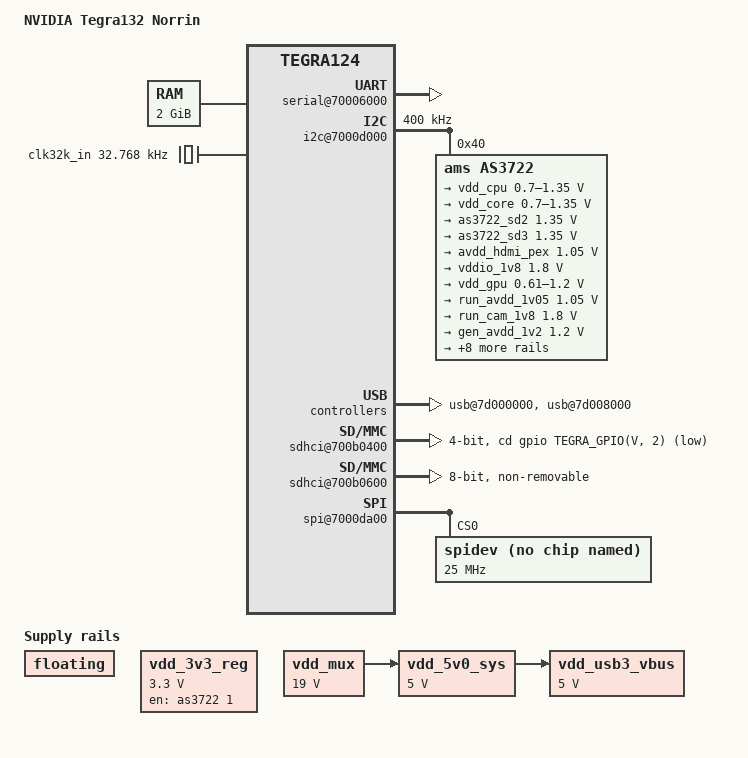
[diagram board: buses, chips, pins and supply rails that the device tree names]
/dts-v1/;

#include <dt-bindings/input/input.h>
#include "tegra132.dtsi"

/ {
	model = "NVIDIA Tegra132 Norrin";
	compatible = "nvidia,norrin", "nvidia,tegra132", "nvidia,tegra124";

	aliases {
		rtc0 = "/i2c@7000d000/as3722@40";
		rtc1 = "/rtc@7000e000";
	};

	memory {
		reg = <0x0 0x80000000 0x0 0x80000000>;
	};

	pinmux@70000868 {
		pinctrl-names = "default";
		pinctrl-0 = <&state_default>;

		state_default: pinmux@0 {
			dap_mclk1_pw4 {
				nvidia,pins = "dap_mclk1_pw4";
				nvidia,function = "extperiph1";
				nvidia,pull = <TEGRA_PIN_PULL_NONE>;
				nvidia,tristate = <TEGRA_PIN_DISABLE>;
				nvidia,enable-input = <TEGRA_PIN_DISABLE>;
			};
			dap2_din_pa4 {
				nvidia,pins = "dap2_din_pa4";
				nvidia,function = "i2s1";
				nvidia,pull = <TEGRA_PIN_PULL_NONE>;
				nvidia,tristate = <TEGRA_PIN_DISABLE>;
				nvidia,enable-input = <TEGRA_PIN_ENABLE>;
			};
			dap2_dout_pa5 {
				nvidia,pins = "dap2_dout_pa5",
						"dap2_fs_pa2",
						"dap2_sclk_pa3";
				nvidia,function = "i2s1";
				nvidia,pull = <TEGRA_PIN_PULL_NONE>;
				nvidia,tristate = <TEGRA_PIN_DISABLE>;
				nvidia,enable-input = <TEGRA_PIN_DISABLE>;
			};
			dap3_dout_pp2 {
				nvidia,pins = "dap3_dout_pp2";
				nvidia,function = "i2s2";
				nvidia,pull = <TEGRA_PIN_PULL_DOWN>;
				nvidia,tristate = <TEGRA_PIN_DISABLE>;
				nvidia,enable-input = <TEGRA_PIN_DISABLE>;
			};
			dvfs_pwm_px0 {
				nvidia,pins = "dvfs_pwm_px0",
						"dvfs_clk_px2";
				nvidia,function = "cldvfs";
				nvidia,pull = <TEGRA_PIN_PULL_NONE>;
				nvidia,tristate = <TEGRA_PIN_DISABLE>;
				nvidia,enable-input = <TEGRA_PIN_DISABLE>;
			};
			ulpi_clk_py0 {
				nvidia,pins = "ulpi_clk_py0",
						"ulpi_nxt_py2",
						"ulpi_stp_py3";
				nvidia,function = "spi1";
				nvidia,pull = <TEGRA_PIN_PULL_NONE>;
				nvidia,tristate = <TEGRA_PIN_DISABLE>;
				nvidia,enable-input = <TEGRA_PIN_DISABLE>;
			};
			ulpi_dir_py1 {
				nvidia,pins = "ulpi_dir_py1";
				nvidia,function = "spi1";
				nvidia,pull = <TEGRA_PIN_PULL_NONE>;
				nvidia,tristate = <TEGRA_PIN_DISABLE>;
				nvidia,enable-input = <TEGRA_PIN_ENABLE>;
			};
			cam_i2c_scl_pbb1 {
				nvidia,pins = "cam_i2c_scl_pbb1",
						"cam_i2c_sda_pbb2";
				nvidia,function = "i2c3";
				nvidia,pull = <TEGRA_PIN_PULL_NONE>;
				nvidia,tristate = <TEGRA_PIN_DISABLE>;
				nvidia,enable-input = <TEGRA_PIN_ENABLE>;
				nvidia,lock = <TEGRA_PIN_DISABLE>;
				nvidia,open-drain = <TEGRA_PIN_ENABLE>;
			};
			gen2_i2c_scl_pt5 {
				nvidia,pins = "gen2_i2c_scl_pt5",
						"gen2_i2c_sda_pt6";
				nvidia,function = "i2c2";
				nvidia,pull = <TEGRA_PIN_PULL_NONE>;
				nvidia,tristate = <TEGRA_PIN_DISABLE>;
				nvidia,enable-input = <TEGRA_PIN_ENABLE>;
				nvidia,lock = <TEGRA_PIN_DISABLE>;
				nvidia,open-drain = <TEGRA_PIN_ENABLE>;
			};
			pj7 {
				nvidia,pins = "pj7";
				nvidia,function = "uartd";
				nvidia,pull = <TEGRA_PIN_PULL_NONE>;
				nvidia,tristate = <TEGRA_PIN_DISABLE>;
				nvidia,enable-input = <TEGRA_PIN_DISABLE>;
			};
			spdif_in_pk6 {
				nvidia,pins = "spdif_in_pk6";
				nvidia,function = "spdif";
				nvidia,pull = <TEGRA_PIN_PULL_DOWN>;
				nvidia,tristate = <TEGRA_PIN_DISABLE>;
				nvidia,enable-input = <TEGRA_PIN_DISABLE>;
			};
			pk7 {
				nvidia,pins = "pk7";
				nvidia,function = "uartd";
				nvidia,pull = <TEGRA_PIN_PULL_NONE>;
				nvidia,tristate = <TEGRA_PIN_DISABLE>;
				nvidia,enable-input = <TEGRA_PIN_DISABLE>;
			};
			pg4 {
				nvidia,pins = "pg4",
						"pg5",
						"pg6",
						"pi3";
				nvidia,function = "spi4";
				nvidia,pull = <TEGRA_PIN_PULL_NONE>;
				nvidia,tristate = <TEGRA_PIN_DISABLE>;
				nvidia,enable-input = <TEGRA_PIN_DISABLE>;
			};
			pg7 {
				nvidia,pins = "pg7";
				nvidia,function = "spi4";
				nvidia,pull = <TEGRA_PIN_PULL_NONE>;
				nvidia,tristate = <TEGRA_PIN_DISABLE>;
				nvidia,enable-input = <TEGRA_PIN_ENABLE>;
			};
			ph1 {
				nvidia,pins = "ph1";
				nvidia,function = "pwm1";
				nvidia,pull = <TEGRA_PIN_PULL_NONE>;
				nvidia,tristate = <TEGRA_PIN_DISABLE>;
				nvidia,enable-input = <TEGRA_PIN_DISABLE>;
			};
			pk0 {
				nvidia,pins = "pk0",
						"kb_row15_ps7",
						"clk_32k_out_pa0";
				nvidia,function = "soc";
				nvidia,pull = <TEGRA_PIN_PULL_UP>;
				nvidia,tristate = <TEGRA_PIN_DISABLE>;
				nvidia,enable-input = <TEGRA_PIN_ENABLE>;
			};
			sdmmc1_clk_pz0 {
				nvidia,pins = "sdmmc1_clk_pz0";
				nvidia,function = "sdmmc1";
				nvidia,pull = <TEGRA_PIN_PULL_NONE>;
				nvidia,tristate = <TEGRA_PIN_DISABLE>;
				nvidia,enable-input = <TEGRA_PIN_ENABLE>;
			};
			sdmmc1_cmd_pz1 {
				nvidia,pins = "sdmmc1_cmd_pz1",
						"sdmmc1_dat0_py7",
						"sdmmc1_dat1_py6",
						"sdmmc1_dat2_py5",
						"sdmmc1_dat3_py4";
				nvidia,function = "sdmmc1";
				nvidia,pull = <TEGRA_PIN_PULL_UP>;
				nvidia,tristate = <TEGRA_PIN_DISABLE>;
				nvidia,enable-input = <TEGRA_PIN_ENABLE>;
			};
			sdmmc3_clk_pa6 {
				nvidia,pins = "sdmmc3_clk_pa6";
				nvidia,function = "sdmmc3";
				nvidia,pull = <TEGRA_PIN_PULL_NONE>;
				nvidia,tristate = <TEGRA_PIN_DISABLE>;
				nvidia,enable-input = <TEGRA_PIN_ENABLE>;
			};
			sdmmc3_cmd_pa7 {
				nvidia,pins = "sdmmc3_cmd_pa7",
						"sdmmc3_dat0_pb7",
						"sdmmc3_dat1_pb6",
						"sdmmc3_dat2_pb5",
						"sdmmc3_dat3_pb4",
						"kb_col4_pq4",
						"sdmmc3_clk_lb_out_pee4",
						"sdmmc3_clk_lb_in_pee5",
						"sdmmc3_cd_n_pv2";
				nvidia,function = "sdmmc3";
				nvidia,pull = <TEGRA_PIN_PULL_UP>;
				nvidia,tristate = <TEGRA_PIN_DISABLE>;
				nvidia,enable-input = <TEGRA_PIN_ENABLE>;
			};
			sdmmc4_clk_pcc4 {
				nvidia,pins = "sdmmc4_clk_pcc4";
				nvidia,function = "sdmmc4";
				nvidia,pull = <TEGRA_PIN_PULL_NONE>;
				nvidia,tristate = <TEGRA_PIN_DISABLE>;
				nvidia,enable-input = <TEGRA_PIN_ENABLE>;
			};
			sdmmc4_cmd_pt7 {
				nvidia,pins = "sdmmc4_cmd_pt7",
						"sdmmc4_dat0_paa0",
						"sdmmc4_dat1_paa1",
						"sdmmc4_dat2_paa2",
						"sdmmc4_dat3_paa3",
						"sdmmc4_dat4_paa4",
						"sdmmc4_dat5_paa5",
						"sdmmc4_dat6_paa6",
						"sdmmc4_dat7_paa7";
				nvidia,function = "sdmmc4";
				nvidia,pull = <TEGRA_PIN_PULL_UP>;
				nvidia,tristate = <TEGRA_PIN_DISABLE>;
				nvidia,enable-input = <TEGRA_PIN_ENABLE>;
			};
			mic_det_l {
				nvidia,pins = "kb_row7_pr7";
				nvidia,function = "rsvd2";
				nvidia,pull = <TEGRA_PIN_PULL_UP>;
				nvidia,tristate = <TEGRA_PIN_DISABLE>;
				nvidia,enable-input = <TEGRA_PIN_ENABLE>;
			};
			kb_row10_ps2 {
				nvidia,pins = "kb_row10_ps2";
				nvidia,function = "uarta";
				nvidia,pull = <TEGRA_PIN_PULL_UP>;
				nvidia,tristate = <TEGRA_PIN_DISABLE>;
				nvidia,enable-input = <TEGRA_PIN_ENABLE>;
			};
			kb_row9_ps1 {
				nvidia,pins = "kb_row9_ps1";
				nvidia,function = "uarta";
				nvidia,pull = <TEGRA_PIN_PULL_NONE>;
				nvidia,tristate = <TEGRA_PIN_DISABLE>;
				nvidia,enable-input = <TEGRA_PIN_DISABLE>;
			};
			pwr_i2c_scl_pz6 {
				nvidia,pins = "pwr_i2c_scl_pz6",
						"pwr_i2c_sda_pz7";
				nvidia,function = "i2cpwr";
				nvidia,pull = <TEGRA_PIN_PULL_NONE>;
				nvidia,tristate = <TEGRA_PIN_DISABLE>;
				nvidia,enable-input = <TEGRA_PIN_ENABLE>;
				nvidia,lock = <TEGRA_PIN_DISABLE>;
				nvidia,open-drain = <TEGRA_PIN_ENABLE>;
			};
			jtag_rtck {
				nvidia,pins = "jtag_rtck";
				nvidia,function = "rtck";
				nvidia,pull = <TEGRA_PIN_PULL_UP>;
				nvidia,tristate = <TEGRA_PIN_DISABLE>;
				nvidia,enable-input = <TEGRA_PIN_DISABLE>;

			};
			clk_32k_in {
				nvidia,pins = "clk_32k_in";
				nvidia,function = "clk";
				nvidia,pull = <TEGRA_PIN_PULL_NONE>;
				nvidia,tristate = <TEGRA_PIN_DISABLE>;
				nvidia,enable-input = <TEGRA_PIN_ENABLE>;
			};
			core_pwr_req {
				nvidia,pins = "core_pwr_req";
				nvidia,function = "pwron";
				nvidia,pull = <TEGRA_PIN_PULL_NONE>;
				nvidia,tristate = <TEGRA_PIN_DISABLE>;
				nvidia,enable-input = <TEGRA_PIN_DISABLE>;
			};
			cpu_pwr_req {
				nvidia,pins = "cpu_pwr_req";
				nvidia,function = "cpu";
				nvidia,pull = <TEGRA_PIN_PULL_NONE>;
				nvidia,tristate = <TEGRA_PIN_DISABLE>;
				nvidia,enable-input = <TEGRA_PIN_DISABLE>;
			};
			kb_col0_ap {
				nvidia,pins = "kb_col0_pq0";
				nvidia,function = "rsvd4";
				nvidia,pull = <TEGRA_PIN_PULL_UP>;
				nvidia,tristate = <TEGRA_PIN_DISABLE>;
				nvidia,enable-input = <TEGRA_PIN_ENABLE>;
			};
			en_vdd_sd {
				nvidia,pins = "kb_row0_pr0";
				nvidia,function = "rsvd4";
				nvidia,pull = <TEGRA_PIN_PULL_NONE>;
				nvidia,tristate = <TEGRA_PIN_DISABLE>;
				nvidia,enable-input = <TEGRA_PIN_DISABLE>;
			};
			lid_open {
				nvidia,pins = "kb_row4_pr4";
				nvidia,function = "rsvd3";
				nvidia,pull = <TEGRA_PIN_PULL_UP>;
				nvidia,tristate = <TEGRA_PIN_DISABLE>;
				nvidia,enable-input = <TEGRA_PIN_ENABLE>;
			};
			pwr_int_n {
				nvidia,pins = "pwr_int_n";
				nvidia,function = "pmi";
				nvidia,pull = <TEGRA_PIN_PULL_UP>;
				nvidia,tristate = <TEGRA_PIN_DISABLE>;
				nvidia,enable-input = <TEGRA_PIN_ENABLE>;
			};
			reset_out_n {
				nvidia,pins = "reset_out_n";
				nvidia,function = "reset_out_n";
				nvidia,pull = <TEGRA_PIN_PULL_NONE>;
				nvidia,tristate = <TEGRA_PIN_DISABLE>;
				nvidia,enable-input = <TEGRA_PIN_DISABLE>;
			};
			clk3_out_pee0 {
				nvidia,pins = "clk3_out_pee0";
				nvidia,function = "extperiph3";
				nvidia,pull = <TEGRA_PIN_PULL_NONE>;
				nvidia,tristate = <TEGRA_PIN_DISABLE>;
				nvidia,enable-input = <TEGRA_PIN_DISABLE>;
			};
			gen1_i2c_scl_pc4 {
				nvidia,pins = "gen1_i2c_scl_pc4",
						"gen1_i2c_sda_pc5";
				nvidia,function = "i2c1";
				nvidia,pull = <TEGRA_PIN_PULL_NONE>;
				nvidia,tristate = <TEGRA_PIN_DISABLE>;
				nvidia,enable-input = <TEGRA_PIN_ENABLE>;
				nvidia,lock = <TEGRA_PIN_DISABLE>;
				nvidia,open-drain = <TEGRA_PIN_ENABLE>;
			};
			hdmi_cec_pee3 {
				nvidia,pins = "hdmi_cec_pee3";
				nvidia,function = "cec";
				nvidia,pull = <TEGRA_PIN_PULL_NONE>;
				nvidia,tristate = <TEGRA_PIN_DISABLE>;
				nvidia,enable-input = <TEGRA_PIN_ENABLE>;
				nvidia,lock = <TEGRA_PIN_DISABLE>;
				nvidia,open-drain = <TEGRA_PIN_DISABLE>;
			};
			hdmi_int_pn7 {
				nvidia,pins = "hdmi_int_pn7";
				nvidia,function = "rsvd1";
				nvidia,pull = <TEGRA_PIN_PULL_DOWN>;
				nvidia,tristate = <TEGRA_PIN_DISABLE>;
				nvidia,enable-input = <TEGRA_PIN_ENABLE>;
			};
			ddc_scl_pv4 {
				nvidia,pins = "ddc_scl_pv4",
						"ddc_sda_pv5";
				nvidia,function = "i2c4";
				nvidia,pull = <TEGRA_PIN_PULL_DOWN>;
				nvidia,tristate = <TEGRA_PIN_DISABLE>;
				nvidia,enable-input = <TEGRA_PIN_ENABLE>;
				nvidia,lock = <TEGRA_PIN_DISABLE>;
				nvidia,rcv-sel = <TEGRA_PIN_PULL_DOWN>;
			};
			usb_vbus_en0_pn4 {
				nvidia,pins = "usb_vbus_en0_pn4",
						"usb_vbus_en1_pn5",
						"usb_vbus_en2_pff1";
				nvidia,function = "usb";
				nvidia,pull = <TEGRA_PIN_PULL_UP>;
				nvidia,tristate = <TEGRA_PIN_ENABLE>;
				nvidia,enable-input = <TEGRA_PIN_ENABLE>;
				nvidia,lock = <TEGRA_PIN_DISABLE>;
				nvidia,open-drain = <TEGRA_PIN_DISABLE>;
			};
			drive_sdio1 {
				nvidia,pins = "drive_sdio1";
				nvidia,high-speed-mode = <TEGRA_PIN_ENABLE>;
				nvidia,schmitt = <TEGRA_PIN_DISABLE>;
				nvidia,low-power-mode = <TEGRA_PIN_LP_DRIVE_DIV_1>;
				nvidia,pull-down-strength = <36>;
				nvidia,pull-up-strength = <20>;
				nvidia,slew-rate-rising = <TEGRA_PIN_SLEW_RATE_SLOW>;
				nvidia,slew-rate-falling = <TEGRA_PIN_SLEW_RATE_SLOW>;
			};
			drive_sdio3 {
				nvidia,pins = "drive_sdio3";
				nvidia,high-speed-mode = <TEGRA_PIN_ENABLE>;
				nvidia,schmitt = <TEGRA_PIN_DISABLE>;
				nvidia,low-power-mode = <TEGRA_PIN_LP_DRIVE_DIV_1>;
				nvidia,pull-down-strength = <22>;
				nvidia,pull-up-strength = <36>;
				nvidia,slew-rate-rising = <TEGRA_PIN_SLEW_RATE_FASTEST>;
				nvidia,slew-rate-falling = <TEGRA_PIN_SLEW_RATE_FASTEST>;
			};
			drive_gma {
				nvidia,pins = "drive_gma";
				nvidia,high-speed-mode = <TEGRA_PIN_ENABLE>;
				nvidia,schmitt = <TEGRA_PIN_DISABLE>;
				nvidia,low-power-mode = <TEGRA_PIN_LP_DRIVE_DIV_1>;
				nvidia,pull-down-strength = <2>;
				nvidia,pull-up-strength = <1>;
				nvidia,slew-rate-rising = <TEGRA_PIN_SLEW_RATE_FASTEST>;
				nvidia,slew-rate-falling = <TEGRA_PIN_SLEW_RATE_FASTEST>;
				nvidia,drive-type = <1>;
			};
			ac_ok {
				nvidia,pins = "pj0";
				nvidia,function = "gmi";
				nvidia,pull = <TEGRA_PIN_PULL_UP>;
				nvidia,tristate = <TEGRA_PIN_ENABLE>;
				nvidia,enable-input = <TEGRA_PIN_ENABLE>;
			};
			codec_irq_l {
				nvidia,pins = "ph4";
				nvidia,function = "gmi";
				nvidia,pull = <TEGRA_PIN_PULL_NONE>;
				nvidia,tristate = <TEGRA_PIN_DISABLE>;
				nvidia,enable-input = <TEGRA_PIN_ENABLE>;
			};
			lcd_bl_en {
				nvidia,pins = "ph2";
				nvidia,function = "gmi";
				nvidia,pull = <TEGRA_PIN_PULL_DOWN>;
				nvidia,tristate = <TEGRA_PIN_DISABLE>;
				nvidia,enable-input = <TEGRA_PIN_DISABLE>;
			};
			touch_irq_l {
				nvidia,pins = "gpio_w3_aud_pw3";
				nvidia,function = "spi6";
				nvidia,pull = <TEGRA_PIN_PULL_NONE>;
				nvidia,tristate = <TEGRA_PIN_ENABLE>;
				nvidia,enable-input = <TEGRA_PIN_ENABLE>;
			};
			tpm_davint_l {
				nvidia,pins = "ph6";
				nvidia,function = "gmi";
				nvidia,pull = <TEGRA_PIN_PULL_NONE>;
				nvidia,tristate = <TEGRA_PIN_ENABLE>;
				nvidia,enable-input = <TEGRA_PIN_ENABLE>;
			};
			ts_irq_l {
				nvidia,pins = "pk2";
				nvidia,function = "gmi";
				nvidia,pull = <TEGRA_PIN_PULL_NONE>;
				nvidia,tristate = <TEGRA_PIN_ENABLE>;
				nvidia,enable-input = <TEGRA_PIN_ENABLE>;
			};
			ts_reset_l {
				nvidia,pins = "pk4";
				nvidia,function = "gmi";
				nvidia,pull = <1>;
				nvidia,tristate = <TEGRA_PIN_DISABLE>;
				nvidia,enable-input = <TEGRA_PIN_DISABLE>;
			};
			ts_shdn_l {
				nvidia,pins = "pk1";
				nvidia,function = "gmi";
				nvidia,pull = <TEGRA_PIN_PULL_UP>;
				nvidia,tristate = <TEGRA_PIN_DISABLE>;
				nvidia,enable-input = <TEGRA_PIN_DISABLE>;
			};
			ph7 {
				nvidia,pins = "ph7";
				nvidia,function = "gmi";
				nvidia,pull = <TEGRA_PIN_PULL_NONE>;
				nvidia,tristate = <TEGRA_PIN_DISABLE>;
				nvidia,enable-input = <TEGRA_PIN_ENABLE>;
			};
			sensor_irq_l {
				nvidia,pins = "pi6";
				nvidia,function = "gmi";
				nvidia,pull = <TEGRA_PIN_PULL_NONE>;
				nvidia,tristate = <TEGRA_PIN_DISABLE>;
				nvidia,enable-input = <TEGRA_PIN_ENABLE>;
			};
			wifi_en {
				nvidia,pins = "gpio_x7_aud_px7";
				nvidia,function = "rsvd4";
				nvidia,pull = <TEGRA_PIN_PULL_NONE>;
				nvidia,tristate = <TEGRA_PIN_DISABLE>;
				nvidia,enable-input = <TEGRA_PIN_DISABLE>;
			};
			chromeos_write_protect {
				nvidia,pins = "kb_row1_pr1";
				nvidia,function = "rsvd4";
				nvidia,pull = <TEGRA_PIN_PULL_NONE>;
				nvidia,tristate = <TEGRA_PIN_DISABLE>;
				nvidia,enable-input = <TEGRA_PIN_ENABLE>;
			};
			hp_det_l {
				nvidia,pins = "pi7";
				nvidia,function = "rsvd1";
				nvidia,pull = <TEGRA_PIN_PULL_NONE>;
				nvidia,tristate = <TEGRA_PIN_DISABLE>;
				nvidia,enable-input = <TEGRA_PIN_ENABLE>;
			};
			soc_warm_reset_l {
				nvidia,pins = "pi5";
				nvidia,function = "gmi";
				nvidia,pull = <TEGRA_PIN_PULL_UP>;
				nvidia,tristate = <TEGRA_PIN_DISABLE>;
				nvidia,enable-input = <TEGRA_PIN_DISABLE>;
			};
		};
	};

	serial@70006000 {
		status = "okay";
	};

	rtc {
		nvidia,pmc-wakeup = <&pmc 1 16 4>;
	};

	i2c@7000d000 {
		status = "okay";
		clock-frequency = <400000>;

		as3722: pmic@40 {
			compatible = "ams,as3722";
			reg = <0x40>;

			interrupts = <GIC_SPI 86 IRQ_TYPE_NONE>;
			interrupt-controller;
			#interrupt-cells = <2>;
			nvidia,pmc-wakeup = <&pmc 1 18 8>;

			gpio-controller;
			#gpio-cells = <2>;

			ams,system-power-controller;

			pinctrl-names = "default";
			pinctrl-0 = <&as3722_default>;

			pinctrl@0 {
				gpio6 {
					pins = "gpio6";
					function = "clk32k-out";
					bias-pull-down;
				};
			};
			as3722_default: pinmux@0 {
				gpio0 {
					pins = "gpio0";
					function = "gpio";
					bias-pull-down;
				};

				gpio1 {
					pins = "gpio1";
					function = "gpio";
					bias-pull-up;
				};

				gpio2_4_7 {
					pins = "gpio2", "gpio4", "gpio7";
					function = "gpio";
					bias-pull-up;
				};

				gpio3 {
					pins = "gpio3";
					function = "gpio";
					bias-high-impedance;
				};

				gpio5 {
					pins = "gpio5";
					function = "clk32k-out";
					bias-pull-down;
				};
			};

			regulators {
				vsup-sd2-supply = <&floating>;
				vsup-sd3-supply = <&floating>;
				vsup-sd4-supply = <&floating>;
				vsup-sd5-supply = <&floating>;
				vin-ldo0-supply = <&as3722_sd2>;
				vin-ldo1-6-supply = <&floating>;
				vin-ldo2-5-7-supply = <&vddio_1v8>;
				vin-ldo3-4-supply = <&floating>;
				vin-ldo9-10-supply = <&floating>;
				vin-ldo11-supply = <&floating>;

				vdd_cpu: sd0 {
					regulator-name = "vdd_cpu";
					regulator-min-microvolt = <700000>;
					regulator-max-microvolt = <1350000>;
					regulator-always-on;
					regulator-suspend-mem-disabled;
					ams,ext-control = <2>;
				};

				sd1 {
					regulator-name = "vdd_core";
					regulator-min-microvolt = <700000>;
					regulator-max-microvolt = <1350000>;
					regulator-max-microamp = <3500000>;
					regulator-always-on;
					regulator-suspend-mem-disabled;
					ams,ext-control = <1>;
					ams,standby-sequence = <6>;
				};

				as3722_sd2: sd2 {
					regulator-name = "vddio_ddr";
					regulator-min-microvolt = <1350000>;
					regulator-max-microvolt = <1350000>;
					regulator-always-on;
					regulator-suspend-mem-enabled;
				};

				as3722_sd3: sd3 {
					regulator-name = "sd3";
					regulator-min-microvolt = <1350000>;
					regulator-max-microvolt = <1350000>;
					regulator-always-on;
					regulator-suspend-mem-enabled;
				};

				avdd_hdmi_pex: sd4 {
					regulator-name = "avdd-hdmi-pex";
					regulator-min-microvolt = <1050000>;
					regulator-max-microvolt = <1050000>;
					regulator-boot-on;
					regulator-always-on;
					regulator-suspend-mem-disabled;
					ams,standby-sequence = <3>;
				};

				vddio_1v8: sd5 {
					regulator-name = "vdd-1v8";
					regulator-min-microvolt = <1800000>;
					regulator-max-microvolt = <1800000>;
					regulator-always-on;
					regulator-suspend-mem-enabled;
				};

				vdd_gpu: sd6 {
					regulator-name = "vdd_gpu";
					regulator-min-microvolt = <610000>;
					regulator-max-microvolt = <1200000>;
					regulator-boot-on;
					regulator-always-on;
					regulator-suspend-mem-enabled;
					regulator-suspend-mem-microvolt = <610000>;
					ams,standby-sequence = <0>;
				};

				run_avdd_1v05: ldo0 {
					regulator-name = "avdd-pll";
					regulator-min-microvolt = <1050000>;
					regulator-max-microvolt = <1050000>;
					regulator-always-on;
					regulator-suspend-mem-disabled;
					ams,ext-control = <1>;
					ams,standby-sequence = <5>;
				};

				run_cam_1v8: ldo1 {
					regulator-name = "vdd_cam";
					regulator-min-microvolt = <1800000>;
					regulator-max-microvolt = <1800000>;
					regulator-suspend-mem-disabled;
				};

				gen_avdd_1v2: ldo2 {
					regulator-name = "vddio_hsic";
					regulator-min-microvolt = <1200000>;
					regulator-max-microvolt = <1200000>;
					regulator-always-on;
					regulator-suspend-mem-disabled;
					ams,standby-sequence = <2>;
				};

				lp0_vdd_rtc_1v0: ldo3 {
					regulator-name = "vdd_rtc";
					regulator-min-microvolt = <1000000>;
					regulator-max-microvolt = <1000000>;
					regulator-always-on;
					regulator-suspend-mem-enabled;
					ams,enable-tracking;
				};

				run_cam_2v8: ldo4 {
					regulator-name = "avdd_cam";
					regulator-min-microvolt = <2800000>;
					regulator-max-microvolt = <2800000>;
					regulator-suspend-mem-disabled;
					ams,standby-sequence = <1>;
				};

				run_cam_front_1v2: ldo5 {
					regulator-name = "vdig";
					regulator-min-microvolt = <1200000>;
					regulator-max-microvolt = <1200000>;
					regulator-suspend-mem-disabled;
				};

				vddio_sdmmc3: ldo6 {
					regulator-name = "vddio_sdmmc";
					regulator-min-microvolt = <3300000>;
					regulator-max-microvolt = <3300000>;
					regulator-suspend-mem-disabled;
				};

				run_cam_rear_en_1v05: ldo7 {
					regulator-name = "vdd_cam1";
					regulator-min-microvolt = <1050000>;
					regulator-max-microvolt = <1050000>;
					regulator-suspend-mem-disabled;
				};

				run_touch_2v8: ldo9 {
					regulator-name = "avdd";
					regulator-min-microvolt = <2800000>;
					regulator-max-microvolt = <2800000>;
					regulator-suspend-mem-disabled;
				};

				run_cam_af_2v8: ldo10 {
					regulator-name = "avdd_af1_cam";
					regulator-min-microvolt = <2800000>;
					regulator-max-microvolt = <2800000>;
					regulator-suspend-mem-disabled;
				};

				run_vpp_fuse_1v8: ldo11 {
					regulator-name = "vpp_fuse";
					regulator-min-microvolt = <1800000>;
					regulator-max-microvolt = <1800000>;
					regulator-suspend-mem-disabled;
				};
			};
		};
	};

	memory-controller@7001b000 {
		emc-table@0 {
			#address-cells = <1>;
			#size-cells = <0>;
			nvidia,ram-code = <0>;
			emc-table@12751 {
				compatible = "nvidia,tegra12-emc-table";
				reg = <12750>;
				clock-frequency = <12750>;
				nvidia,revision = <0x19>;
				nvidia,emc-min-mv = <800>;
				nvidia,gk20a-min-mv = <800>;
				nvidia,src-sel-reg = <0x4000003e>;
				nvidia,burst-regs-num = <165>;
				nvidia,burst-up-down-regs-num = <31>;
				nvidia,emc-registers = <0x00000000 0x00000003
					0x00000000 0x00000000 0x00000000 0x00000004
					0x0000000a 0x00000003 0x0000000b 0x00000000
					0x00000000 0x00000003 0x00000003 0x00000000
					0x00000006 0x00000006 0x00000006 0x00000002
					0x00000000 0x00000005 0x00000005 0x00010000
					0x00000003 0x00000000 0x00000000 0x00000000
					0x00000000 0x00000004 0x0000000c 0x0000000d
					0x0000000f 0x00000060 0x00000000 0x00000018
					0x00000002 0x00000002 0x00000001 0x00000000
					0x00000007 0x0000000f 0x00000005 0x00000005
					0x00000004 0x00000005 0x00000004 0x00000000
					0x00000000 0x00000005 0x00000005 0x00000064
					0x00000000 0x00000000 0x00000000 0x106aa298
					0x002c00a0 0x00008000 0x00064000 0x00064000
					0x00064000 0x00064000 0x00064000 0x00064000
					0x00064000 0x00064000 0x00064000 0x00064000
					0x00064000 0x00064000 0x00064000 0x00064000
					0x00064000 0x00064000 0x00000000 0x00000000
					0x00000000 0x00000000 0x00000000 0x00000000
					0x00000000 0x00000000 0x00000000 0x00000000
					0x00014000 0x00000000 0x00000000 0x00014000
					0x00000000 0x00000000 0x00000000 0x00000000
					0x00000000 0x00000000 0x00000000 0x00000000
					0x00000000 0x00000000 0x00000000 0x00000000
					0x00000000 0x00000000 0x00000000 0x00000000
					0x00000000 0x00000000 0x00000000 0x00000000
					0x00000000 0x00000000 0x00000000 0x00000000
					0x000fc000 0x000fc000 0x000fc000 0x000fc000
					0x0000fc00 0x0000fc00 0x0000fc00 0x0000fc00
					0x10000280 0x00000000 0x00111111 0x0130b118
					0x00000000 0x00000000 0x77ffc081 0x00000707
					0x81f1f108 0x07070004 0x0000003f 0x016eeeee
					0x51451400 0x00514514 0x00514514 0x51451400
					0x0000003f 0x00000007 0x00000000 0x00000000
					0x00000042 0x000e000e 0x000e000e 0x00000000
					0x00000003 0x0000f2f3 0x800001c5 0x0000000a
					0x40040001 0x8000000a 0x00000001 0x00000001
					0x00000002 0x00000000 0x00000002 0x00000001
					0x00000002 0x00000008 0x00000003 0x00000002
					0x00000003 0x00000006 0x06030203 0x000a0402
					0x77e30303 0x70000f03 0x001f0000>;
				nvidia,emc-burst-up-down-regs = <0x00000001 0x00000007
					0x00ff00ff 0x00ff00ff 0x00ff00ff 0x00ff00ff
					0x00ff00ff 0x00ff00ff 0x00ff00ff 0x00ff0049
					0x00ff0080 0x00ff0004 0x00ff0004 0x000800ff
					0x000000ff 0x00ff0004 0x00ff00ff 0x00ff00ff
					0x00ff0024 0x00ff00ff 0x000000ff 0x000000ff
					0x00ff00ff 0x000000ff 0x00ff00ff 0x00ff00ff
					0x00ff00ff 0x00ff00ff 0x00ff00ff 0x00ff00ff
					0x00ff00ff>;
				nvidia,emc-zcal-cnt-long = <0x00000042>;
				nvidia,emc-acal-interval = <0x001fffff>;
				nvidia,emc-ctt-term-ctrl = <0x00000802>;
				nvidia,emc-cfg = <0x73240000>;
				nvidia,emc-cfg-2 = <0x000008c5>;
				nvidia,emc-sel-dpd-ctrl = <0x00040128>;
				nvidia,emc-cfg-dig-dll = <0x002c0068>;
				nvidia,emc-bgbias-ctl0 = <0x00000008>;
				nvidia,emc-auto-cal-config2 = <0x00000000>;
				nvidia,emc-auto-cal-config3 = <0x00000000>;
				nvidia,emc-auto-cal-config = <0xa1430000>;
				nvidia,emc-mode-reset = <0x80001221>;
				nvidia,emc-mode-1 = <0x80100003>;
				nvidia,emc-mode-2 = <0x80200008>;
				nvidia,emc-mode-4 = <0x00000000>;
				nvidia,emc-clock-latency-change = <57820>;
			};
			emc-table@20400 {
				compatible = "nvidia,tegra12-emc-table";
				reg = <20400>;
				clock-frequency = <20400>;
				nvidia,revision = <0x19>;
				nvidia,emc-min-mv = <800>;
				nvidia,gk20a-min-mv = <800>;
				nvidia,src-sel-reg = <0x40000026>;
				nvidia,burst-regs-num = <165>;
				nvidia,burst-up-down-regs-num = <31>;
				nvidia,emc-registers = <0x00000000 0x00000005
					0x00000000 0x00000000 0x00000000 0x00000004
					0x0000000a 0x00000003 0x0000000b 0x00000000
					0x00000000 0x00000003 0x00000003 0x00000000
					0x00000006 0x00000006 0x00000006 0x00000002
					0x00000000 0x00000005 0x00000005 0x00010000
					0x00000003 0x00000000 0x00000000 0x00000000
					0x00000000 0x00000004 0x0000000c 0x0000000d
					0x0000000f 0x0000009a 0x00000000 0x00000026
					0x00000002 0x00000002 0x00000001 0x00000000
					0x00000007 0x0000000f 0x00000006 0x00000006
					0x00000004 0x00000005 0x00000004 0x00000000
					0x00000000 0x00000005 0x00000005 0x000000a0
					0x00000000 0x00000000 0x00000000 0x106aa298
					0x002c00a0 0x00008000 0x00064000 0x00064000
					0x00064000 0x00064000 0x00064000 0x00064000
					0x00064000 0x00064000 0x00064000 0x00064000
					0x00064000 0x00064000 0x00064000 0x00064000
					0x00064000 0x00064000 0x00000000 0x00000000
					0x00000000 0x00000000 0x00000000 0x00000000
					0x00000000 0x00000000 0x00000000 0x00000000
					0x00014000 0x00000000 0x00000000 0x00014000
					0x00000000 0x00000000 0x00000000 0x00000000
					0x00000000 0x00000000 0x00000000 0x00000000
					0x00000000 0x00000000 0x00000000 0x00000000
					0x00000000 0x00000000 0x00000000 0x00000000
					0x00000000 0x00000000 0x00000000 0x00000000
					0x00000000 0x00000000 0x00000000 0x00000000
					0x000fc000 0x000fc000 0x000fc000 0x000fc000
					0x0000fc00 0x0000fc00 0x0000fc00 0x0000fc00
					0x10000280 0x00000000 0x00111111 0x0130b118
					0x00000000 0x00000000 0x77ffc081 0x00000707
					0x81f1f108 0x07070004 0x0000003f 0x016eeeee
					0x51451400 0x00514514 0x00514514 0x51451400
					0x0000003f 0x0000000b 0x00000000 0x00000000
					0x00000042 0x000e000e 0x000e000e 0x00000000
					0x00000003 0x0000f2f3 0x8000023a 0x0000000a
					0x40020001 0x80000012 0x00000001 0x00000001
					0x00000002 0x00000000 0x00000002 0x00000001
					0x00000002 0x00000008 0x00000003 0x00000002
					0x00000003 0x00000006 0x06030203 0x000a0402
					0x76230303 0x70000f03 0x001f0000>;
				nvidia,emc-burst-up-down-regs = <0x00000001 0x0000000a
					0x00ff00ff 0x00ff00ff 0x00ff00ff 0x00ff00ff
					0x00ff00ff 0x00ff00ff 0x00ff00ff 0x00ff0049
					0x00ff0080 0x00ff0004 0x00ff0004 0x000800ff
					0x000000ff 0x00ff0004 0x00ff00ff 0x00ff00ff
					0x00ff0024 0x00ff00ff 0x000000ff 0x000000ff
					0x00ff00ff 0x000000ff 0x00ff00ff 0x00ff00ff
					0x00ff00ff 0x00ff00ff 0x00ff00ff 0x00ff00ff
					0x00ff00ff>;
				nvidia,emc-zcal-cnt-long = <0x00000042>;
				nvidia,emc-acal-interval = <0x001fffff>;
				nvidia,emc-ctt-term-ctrl = <0x00000802>;
				nvidia,emc-cfg = <0x73240000>;
				nvidia,emc-cfg-2 = <0x000008c5>;
				nvidia,emc-sel-dpd-ctrl = <0x00040128>;
				nvidia,emc-cfg-dig-dll = <0x002c0068>;
				nvidia,emc-bgbias-ctl0 = <0x00000008>;
				nvidia,emc-auto-cal-config2 = <0x00000000>;
				nvidia,emc-auto-cal-config3 = <0x00000000>;
				nvidia,emc-auto-cal-config = <0xa1430000>;
				nvidia,emc-mode-reset = <0x80001221>;
				nvidia,emc-mode-1 = <0x80100003>;
				nvidia,emc-mode-2 = <0x80200008>;
				nvidia,emc-mode-4 = <0x00000000>;
				nvidia,emc-clock-latency-change = <35610>;
			};
			emc-table@40800 {
				compatible = "nvidia,tegra12-emc-table";
				reg = <40800>;
				clock-frequency = <40800>;
				nvidia,revision = <0x19>;
				nvidia,emc-min-mv = <800>;
				nvidia,gk20a-min-mv = <800>;
				nvidia,src-sel-reg = <0x40000012>;
				nvidia,burst-regs-num = <165>;
				nvidia,burst-up-down-regs-num = <31>;
				nvidia,emc-registers = <0x00000001 0x0000000a
					0x00000000 0x00000001 0x00000000 0x00000004
					0x0000000a 0x00000003 0x0000000b 0x00000000
					0x00000000 0x00000003 0x00000003 0x00000000
					0x00000006 0x00000006 0x00000006 0x00000002
					0x00000000 0x00000005 0x00000005 0x00010000
					0x00000003 0x00000000 0x00000000 0x00000000
					0x00000000 0x00000004 0x0000000c 0x0000000d
					0x0000000f 0x00000134 0x00000000 0x0000004d
					0x00000002 0x00000002 0x00000001 0x00000000
					0x00000008 0x0000000f 0x0000000c 0x0000000c
					0x00000004 0x00000005 0x00000004 0x00000000
					0x00000000 0x00000005 0x00000005 0x0000013f
					0x00000000 0x00000000 0x00000000 0x106aa298
					0x002c00a0 0x00008000 0x00064000 0x00064000
					0x00064000 0x00064000 0x00064000 0x00064000
					0x00064000 0x00064000 0x00064000 0x00064000
					0x00064000 0x00064000 0x00064000 0x00064000
					0x00064000 0x00064000 0x00000000 0x00000000
					0x00000000 0x00000000 0x00000000 0x00000000
					0x00000000 0x00000000 0x00000000 0x00000000
					0x00014000 0x00000000 0x00000000 0x00014000
					0x00000000 0x00000000 0x00000000 0x00000000
					0x00000000 0x00000000 0x00000000 0x00000000
					0x00000000 0x00000000 0x00000000 0x00000000
					0x00000000 0x00000000 0x00000000 0x00000000
					0x00000000 0x00000000 0x00000000 0x00000000
					0x00000000 0x00000000 0x00000000 0x00000000
					0x000fc000 0x000fc000 0x000fc000 0x000fc000
					0x0000fc00 0x0000fc00 0x0000fc00 0x0000fc00
					0x10000280 0x00000000 0x00111111 0x0130b118
					0x00000000 0x00000000 0x77ffc081 0x00000707
					0x81f1f108 0x07070004 0x0000003f 0x016eeeee
					0x51451400 0x00514514 0x00514514 0x51451400
					0x0000003f 0x00000015 0x00000000 0x00000000
					0x00000042 0x000e000e 0x000e000e 0x00000000
					0x00000003 0x0000f2f3 0x80000370 0x0000000a
					0xa0000001 0x80000017 0x00000001 0x00000001
					0x00000002 0x00000000 0x00000002 0x00000001
					0x00000002 0x00000008 0x00000003 0x00000002
					0x00000003 0x00000006 0x06030203 0x000a0402
					0x74a30303 0x70000f03 0x001f0000>;
				nvidia,emc-burst-up-down-regs = <0x00000001 0x00000014
					0x00ff00ff 0x00ff00ff 0x00ff00ff 0x00ff00ff
					0x00ff00ff 0x00ff00ff 0x00ff00ff 0x00ff0049
					0x00ff0080 0x00ff0004 0x00ff0004 0x000800ff
					0x000000ff 0x00ff0004 0x00ff00ff 0x00ff00ff
					0x00ff0024 0x00ff00ff 0x000000ff 0x000000ff
					0x00ff00ff 0x000000ff 0x00ff00ff 0x00ff00ff
					0x00ff00ff 0x00ff00ff 0x00ff00ff 0x00ff00ff
					0x00ff00ff>;
				nvidia,emc-zcal-cnt-long = <0x00000042>;
				nvidia,emc-acal-interval = <0x001fffff>;
				nvidia,emc-ctt-term-ctrl = <0x00000802>;
				nvidia,emc-cfg = <0x73240000>;
				nvidia,emc-cfg-2 = <0x000008c5>;
				nvidia,emc-sel-dpd-ctrl = <0x00040128>;
				nvidia,emc-cfg-dig-dll = <0x002c0068>;
				nvidia,emc-bgbias-ctl0 = <0x00000008>;
				nvidia,emc-auto-cal-config2 = <0x00000000>;
				nvidia,emc-auto-cal-config3 = <0x00000000>;
				nvidia,emc-auto-cal-config = <0xa1430000>;
				nvidia,emc-mode-reset = <0x80001221>;
				nvidia,emc-mode-1 = <0x80100003>;
				nvidia,emc-mode-2 = <0x80200008>;
				nvidia,emc-mode-4 = <0x00000000>;
				nvidia,emc-clock-latency-change = <20850>;
			};
			emc-table@68000 {
				compatible = "nvidia,tegra12-emc-table";
				reg = <68000>;
				clock-frequency = <68000>;
				nvidia,revision = <0x19>;
				nvidia,emc-min-mv = <800>;
				nvidia,gk20a-min-mv = <800>;
				nvidia,src-sel-reg = <0x4000000a>;
				nvidia,burst-regs-num = <165>;
				nvidia,burst-up-down-regs-num = <31>;
				nvidia,emc-registers = <0x00000003 0x00000011
					0x00000000 0x00000002 0x00000000 0x00000004
					0x0000000a 0x00000003 0x0000000b 0x00000000
					0x00000000 0x00000003 0x00000003 0x00000000
					0x00000006 0x00000006 0x00000006 0x00000002
					0x00000000 0x00000005 0x00000005 0x00010000
					0x00000003 0x00000000 0x00000000 0x00000000
					0x00000000 0x00000004 0x0000000c 0x0000000d
					0x0000000f 0x00000202 0x00000000 0x00000080
					0x00000002 0x00000002 0x00000001 0x00000000
					0x0000000f 0x0000000f 0x00000013 0x00000013
					0x00000004 0x00000005 0x00000004 0x00000001
					0x00000000 0x00000005 0x00000005 0x00000213
					0x00000000 0x00000000 0x00000000 0x106aa298
					0x002c00a0 0x00008000 0x00064000 0x00064000
					0x00064000 0x00064000 0x00064000 0x00064000
					0x00064000 0x00064000 0x00064000 0x00064000
					0x00064000 0x00064000 0x00064000 0x00064000
					0x00064000 0x00064000 0x00000000 0x00000000
					0x00000000 0x00000000 0x00000000 0x00000000
					0x00000000 0x00000000 0x00000000 0x00000000
					0x00014000 0x00000000 0x00000000 0x00014000
					0x00000000 0x00000000 0x00000000 0x00000000
					0x00000000 0x00000000 0x00000000 0x00000000
					0x00000000 0x00000000 0x00000000 0x00000000
					0x00000000 0x00000000 0x00000000 0x00000000
					0x00000000 0x00000000 0x00000000 0x00000000
					0x00000000 0x00000000 0x00000000 0x00000000
					0x000fc000 0x000fc000 0x000fc000 0x000fc000
					0x0000fc00 0x0000fc00 0x0000fc00 0x0000fc00
					0x10000280 0x00000000 0x00111111 0x0130b118
					0x00000000 0x00000000 0x77ffc081 0x00000707
					0x81f1f108 0x07070004 0x0000003f 0x016eeeee
					0x51451400 0x00514514 0x00514514 0x51451400
					0x0000003f 0x00000022 0x00000000 0x00000000
					0x00000042 0x000e000e 0x000e000e 0x00000000
					0x00000003 0x0000f2f3 0x8000050e 0x0000000a
					0x00000001 0x8000001e 0x00000001 0x00000001
					0x00000002 0x00000000 0x00000002 0x00000001
					0x00000002 0x00000008 0x00000003 0x00000002
					0x00000003 0x00000006 0x06030203 0x000a0402
					0x74230403 0x70000f03 0x001f0000>;
				nvidia,emc-burst-up-down-regs = <0x00000001 0x00000021
					0x00ff00ff 0x00ff00ff 0x00ff00b0 0x00ff00ff
					0x00ff00ec 0x00ff00ff 0x00ff00ec 0x00e90049
					0x00ff0080 0x00ff0004 0x00ff0004 0x000800ff
					0x000000ff 0x00ff0004 0x00ff00ff 0x00ff00a3
					0x00ff0024 0x00ff00ff 0x000000ff 0x000000ef
					0x00ff00ff 0x000000ef 0x00ff00ff 0x00ff00ff
					0x00ee00ef 0x00ff00ff 0x00ff00ff 0x00ff00ff
					0x00ff00ff>;
				nvidia,emc-zcal-cnt-long = <0x00000042>;
				nvidia,emc-acal-interval = <0x001fffff>;
				nvidia,emc-ctt-term-ctrl = <0x00000802>;
				nvidia,emc-cfg = <0x73240000>;
				nvidia,emc-cfg-2 = <0x000008c5>;
				nvidia,emc-sel-dpd-ctrl = <0x00040128>;
				nvidia,emc-cfg-dig-dll = <0x002c0068>;
				nvidia,emc-bgbias-ctl0 = <0x00000008>;
				nvidia,emc-auto-cal-config2 = <0x00000000>;
				nvidia,emc-auto-cal-config3 = <0x00000000>;
				nvidia,emc-auto-cal-config = <0xa1430000>;
				nvidia,emc-mode-reset = <0x80001221>;
				nvidia,emc-mode-1 = <0x80100003>;
				nvidia,emc-mode-2 = <0x80200008>;
				nvidia,emc-mode-4 = <0x00000000>;
				nvidia,emc-clock-latency-change = <10720>;
			};
			emc-table@102000 {
				compatible = "nvidia,tegra12-emc-table";
				reg = <102000>;
				clock-frequency = <102000>;
				nvidia,revision = <0x19>;
				nvidia,emc-min-mv = <800>;
				nvidia,gk20a-min-mv = <800>;
				nvidia,src-sel-reg = <0x40000006>;
				nvidia,burst-regs-num = <165>;
				nvidia,burst-up-down-regs-num = <31>;
				nvidia,emc-registers = <0x00000004 0x0000001a
					0x00000000 0x00000003 0x00000001 0x00000004
					0x0000000a 0x00000003 0x0000000b 0x00000001
					0x00000001 0x00000003 0x00000003 0x00000000
					0x00000006 0x00000006 0x00000006 0x00000002
					0x00000000 0x00000005 0x00000005 0x00010000
					0x00000003 0x00000000 0x00000000 0x00000000
					0x00000000 0x00000004 0x0000000c 0x0000000d
					0x0000000f 0x00000304 0x00000000 0x000000c1
					0x00000002 0x00000002 0x00000001 0x00000000
					0x00000018 0x0000000f 0x0000001c 0x0000001c
					0x00000004 0x00000005 0x00000004 0x00000002
					0x00000000 0x00000005 0x00000005 0x0000031c
					0x00000000 0x00000000 0x00000000 0x106aa298
					0x002c00a0 0x00008000 0x00064000 0x00064000
					0x00064000 0x00064000 0x00064000 0x00064000
					0x00064000 0x00064000 0x00064000 0x00064000
					0x00064000 0x00064000 0x00064000 0x00064000
					0x00064000 0x00064000 0x00000000 0x00000000
					0x00000000 0x00000000 0x00000000 0x00000000
					0x00000000 0x00000000 0x00000000 0x00000000
					0x00014000 0x00000000 0x00000000 0x00014000
					0x00000000 0x00000000 0x00000000 0x00000000
					0x00000000 0x00000000 0x00000000 0x00000000
					0x00000000 0x00000000 0x00000000 0x00000000
					0x00000000 0x00000000 0x00000000 0x00000000
					0x00000000 0x00000000 0x00000000 0x00000000
					0x00000000 0x00000000 0x00000000 0x00000000
					0x000fc000 0x000fc000 0x000fc000 0x000fc000
					0x0000fc00 0x0000fc00 0x0000fc00 0x0000fc00
					0x10000280 0x00000000 0x00111111 0x0130b118
					0x00000000 0x00000000 0x77ffc081 0x00000707
					0x81f1f108 0x07070004 0x0000003f 0x016eeeee
					0x51451400 0x00514514 0x00514514 0x51451400
					0x0000003f 0x00000033 0x00000000 0x00000000
					0x00000042 0x000e000e 0x000e000e 0x00000000
					0x00000003 0x0000f2f3 0x80000713 0x0000000a
					0x08000001 0x80000026 0x00000001 0x00000001
					0x00000003 0x00000000 0x00000002 0x00000001
					0x00000002 0x00000008 0x00000003 0x00000002
					0x00000003 0x00000006 0x06030203 0x000a0403
					0x73c30504 0x70000f03 0x001f0000>;
				nvidia,emc-burst-up-down-regs = <0x00000001 0x00000031
					0x00ff00da 0x00ff00da 0x00ff0075 0x00ff00ff
					0x00ff009d 0x00ff00ff 0x00ff009d 0x009b0049
					0x00ff0080 0x00ff0004 0x00ff0004 0x000800ad
					0x000000ff 0x00ff0004 0x00ff00c6 0x00ff006d
					0x00ff0024 0x00ff00d6 0x000000ff 0x0000009f
					0x00ff00ff 0x0000009f 0x00ff00ff 0x00ff00ff
					0x009f00a0 0x00ff00ff 0x00ff00ff 0x00ff00ff
					0x00ff00da>;
				nvidia,emc-zcal-cnt-long = <0x00000042>;
				nvidia,emc-acal-interval = <0x001fffff>;
				nvidia,emc-ctt-term-ctrl = <0x00000802>;
				nvidia,emc-cfg = <0x73240000>;
				nvidia,emc-cfg-2 = <0x000008c5>;
				nvidia,emc-sel-dpd-ctrl = <0x00040128>;
				nvidia,emc-cfg-dig-dll = <0x002c0068>;
				nvidia,emc-bgbias-ctl0 = <0x00000008>;
				nvidia,emc-auto-cal-config2 = <0x00000000>;
				nvidia,emc-auto-cal-config3 = <0x00000000>;
				nvidia,emc-auto-cal-config = <0xa1430000>;
				nvidia,emc-mode-reset = <0x80001221>;
				nvidia,emc-mode-1 = <0x80100003>;
				nvidia,emc-mode-2 = <0x80200008>;
				nvidia,emc-mode-4 = <0x00000000>;
				nvidia,emc-clock-latency-change = <6890>;
			};
			emc-table@204000 {
				compatible = "nvidia,tegra12-emc-table";
				reg = <204000>;
				clock-frequency = <204000>;
				nvidia,revision = <0x19>;
				nvidia,emc-min-mv = <800>;
				nvidia,gk20a-min-mv = <800>;
				nvidia,src-sel-reg = <0x40000002>;
				nvidia,burst-regs-num = <165>;
				nvidia,burst-up-down-regs-num = <31>;
				nvidia,emc-registers = <0x00000009 0x00000035
					0x00000000 0x00000006 0x00000002 0x00000005
					0x0000000a 0x00000003 0x0000000b 0x00000002
					0x00000002 0x00000003 0x00000003 0x00000000
					0x00000005 0x00000005 0x00000006 0x00000002
					0x00000000 0x00000004 0x00000006 0x00010000
					0x00000003 0x00000000 0x00000000 0x00000000
					0x00000000 0x00000003 0x0000000d 0x0000000f
					0x00000011 0x00000607 0x00000000 0x00000181
					0x00000002 0x00000002 0x00000001 0x00000000
					0x00000032 0x0000000f 0x00000038 0x00000038
					0x00000004 0x00000005 0x00000004 0x00000006
					0x00000000 0x00000005 0x00000005 0x00000638
					0x00000000 0x00000000 0x00000000 0x106aa298
					0x002c00a0 0x00008000 0x00064000 0x00064000
					0x00064000 0x00064000 0x00064000 0x00064000
					0x00064000 0x00064000 0x00064000 0x00064000
					0x00064000 0x00064000 0x00064000 0x00064000
					0x00064000 0x00064000 0x00000000 0x00000000
					0x00000000 0x00000000 0x00000000 0x00000000
					0x00000000 0x00000000 0x00000000 0x00000000
					0x00014000 0x00000000 0x00000000 0x00014000
					0x00000000 0x00000000 0x00000000 0x00000000
					0x00000000 0x00000000 0x00000000 0x00000000
					0x00000000 0x00000000 0x00000000 0x00000000
					0x00000000 0x00000000 0x00000000 0x00000000
					0x00000000 0x00000000 0x00000000 0x00000000
					0x00000000 0x00000000 0x00000000 0x00000000
					0x00090000 0x00090000 0x00090000 0x00090000
					0x00009000 0x00009000 0x00009000 0x00009000
					0x10000280 0x00000000 0x00111111 0x0130b118
					0x00000000 0x00000000 0x77ffc081 0x00000707
					0x81f1f108 0x07070004 0x0000003f 0x016eeeee
					0x51451400 0x00514514 0x00514514 0x51451400
					0x0000003f 0x00000066 0x00000000 0x00020000
					0x00000100 0x000e000e 0x000e000e 0x00000000
					0x00000003 0x0000d2b3 0x80000d22 0x0000000a
					0x01000003 0x80000040 0x00000001 0x00000001
					0x00000004 0x00000002 0x00000003 0x00000001
					0x00000002 0x00000008 0x00000003 0x00000002
					0x00000004 0x00000006 0x06040203 0x000a0404
					0x73840a05 0x70000f03 0x001f0000>;
				nvidia,emc-burst-up-down-regs = <0x00000001 0x00000062
					0x00ff006d 0x00ff006d 0x00ff003c 0x00ff00af
					0x00ff004f 0x00ff00af 0x00ff004f 0x004e0049
					0x00ff0080 0x00ff0004 0x00ff0004 0x00080057
					0x000000ff 0x00ff0004 0x00ff0063 0x00ff0036
					0x00ff0024 0x00ff006b 0x000000ff 0x00000050
					0x00ff00ff 0x00000050 0x00ff00ff 0x00d400ff
					0x00510050 0x00ff00ff 0x00ff00ff 0x00ff00c6
					0x00ff006d>;
				nvidia,emc-zcal-cnt-long = <0x00000042>;
				nvidia,emc-acal-interval = <0x001fffff>;
				nvidia,emc-ctt-term-ctrl = <0x00000802>;
				nvidia,emc-cfg = <0x73240000>;
				nvidia,emc-cfg-2 = <0x0000088d>;
				nvidia,emc-sel-dpd-ctrl = <0x00040008>;
				nvidia,emc-cfg-dig-dll = <0x002c0068>;
				nvidia,emc-bgbias-ctl0 = <0x00000008>;
				nvidia,emc-auto-cal-config2 = <0x00000000>;
				nvidia,emc-auto-cal-config3 = <0x00000000>;
				nvidia,emc-auto-cal-config = <0xa1430000>;
				nvidia,emc-mode-reset = <0x80001221>;
				nvidia,emc-mode-1 = <0x80100003>;
				nvidia,emc-mode-2 = <0x80200008>;
				nvidia,emc-mode-4 = <0x00000000>;
				nvidia,emc-clock-latency-change = <3420>;
			};
			emc-table@300000 {
				compatible = "nvidia,tegra12-emc-table";
				reg = <300000>;
				clock-frequency = <300000>;
				nvidia,revision = <0x19>;
				nvidia,emc-min-mv = <820>;
				nvidia,gk20a-min-mv = <820>;
				nvidia,src-sel-reg = <0x20000002>;
				nvidia,burst-regs-num = <165>;
				nvidia,burst-up-down-regs-num = <31>;
				nvidia,emc-registers = <0x0000000d 0x0000004d
					0x00000000 0x00000009 0x00000003 0x00000004
					0x00000008 0x00000002 0x00000009 0x00000003
					0x00000003 0x00000002 0x00000002 0x00000000
					0x00000003 0x00000003 0x00000005 0x00000002
					0x00000000 0x00000002 0x00000007 0x00020000
					0x00000003 0x00000000 0x00000000 0x00000000
					0x00000000 0x00000001 0x0000000e 0x00000010
					0x00000012 0x000008e4 0x00000000 0x00000239
					0x00000001 0x00000008 0x00000001 0x00000000
					0x0000004b 0x0000000e 0x00000052 0x00000200
					0x00000004 0x00000005 0x00000004 0x00000008
					0x00000000 0x00000005 0x00000005 0x00000924
					0x00000000 0x00000000 0x00000000 0x104ab098
					0x002c00a0 0x00008000 0x00030000 0x00030000
					0x00030000 0x00030000 0x00030000 0x00030000
					0x00030000 0x00030000 0x00030000 0x00030000
					0x00030000 0x00030000 0x00030000 0x00030000
					0x00030000 0x00030000 0x00000000 0x00000000
					0x00000000 0x00000000 0x00000000 0x00000000
					0x00000000 0x00000000 0x00088000 0x00088000
					0x00000000 0x00088000 0x00088000 0x00000000
					0x00000000 0x00000000 0x00000000 0x00000000
					0x00000000 0x00000000 0x00000000 0x00000000
					0x00000000 0x00000000 0x00000000 0x00000000
					0x00000000 0x00000000 0x00000000 0x00000000
					0x00000000 0x00000000 0x00000000 0x00000000
					0x00000000 0x00000000 0x00000000 0x00000000
					0x00060000 0x00060000 0x00060000 0x00060000
					0x00006000 0x00006000 0x00006000 0x00006000
					0x10000280 0x00000000 0x00111111 0x01231339
					0x00000000 0x00000000 0x77ffc081 0x00000000
					0x81f1f108 0x07070004 0x00000000 0x016eeeee
					0x51451420 0x00514514 0x00514514 0x51451400
					0x0000003f 0x00000096 0x00000000 0x00020000
					0x00000100 0x0173000e 0x0173000e 0x00000000
					0x00000003 0x000052a3 0x800012d7 0x00000009
					0x08000004 0x80000040 0x00000001 0x00000002
					0x00000007 0x00000004 0x00000004 0x00000001
					0x00000002 0x00000007 0x00000002 0x00000002
					0x00000004 0x00000006 0x06040202 0x000b0607
					0x77450e08 0x70000f03 0x001f0000>;
				nvidia,emc-burst-up-down-regs = <0x00000004 0x00000090
					0x00ff004a 0x00ff004a 0x00ff003c 0x00ff0090
					0x00ff0041 0x00ff0090 0x00ff0041 0x00350049
					0x00ff0080 0x00ff0004 0x00ff0004 0x0008003b
					0x000000ff 0x00ff0004 0x00ff0043 0x00ff002d
					0x00ff0024 0x00ff0049 0x000000ff 0x00000036
					0x00ff00ff 0x00000036 0x00ff00ff 0x00d400ff
					0x00510036 0x00ff00ff 0x00ff00ff 0x00ff0087
					0x00ff004a>;
				nvidia,emc-zcal-cnt-long = <0x00000042>;
				nvidia,emc-acal-interval = <0x001fffff>;
				nvidia,emc-ctt-term-ctrl = <0x00000802>;
				nvidia,emc-cfg = <0x73340000>;
				nvidia,emc-cfg-2 = <0x000008d5>;
				nvidia,emc-sel-dpd-ctrl = <0x00040128>;
				nvidia,emc-cfg-dig-dll = <0x002c0068>;
				nvidia,emc-bgbias-ctl0 = <0x00000000>;
				nvidia,emc-auto-cal-config2 = <0x00000000>;
				nvidia,emc-auto-cal-config3 = <0x00000000>;
				nvidia,emc-auto-cal-config = <0xa1430000>;
				nvidia,emc-mode-reset = <0x80000321>;
				nvidia,emc-mode-1 = <0x80100002>;
				nvidia,emc-mode-2 = <0x80200000>;
				nvidia,emc-mode-4 = <0x00000000>;
				nvidia,emc-clock-latency-change = <2680>;
			};
			emc-table@396000 {
				compatible = "nvidia,tegra12-emc-table";
				reg = <396000>;
				clock-frequency = <396000>;
				nvidia,revision = <0x19>;
				nvidia,emc-min-mv = <850>;
				nvidia,gk20a-min-mv = <850>;
				nvidia,src-sel-reg = <0x00000002>;
				nvidia,burst-regs-num = <165>;
				nvidia,burst-up-down-regs-num = <31>;
				nvidia,emc-registers = <0x00000011 0x00000066
					0x00000000 0x0000000c 0x00000004 0x00000005
					0x00000008 0x00000002 0x0000000a 0x00000004
					0x00000004 0x00000002 0x00000002 0x00000000
					0x00000003 0x00000003 0x00000005 0x00000002
					0x00000000 0x00000001 0x00000008 0x00020000
					0x00000003 0x00000000 0x00000000 0x00000000
					0x00000000 0x00000000 0x0000000f 0x00000010
					0x00000012 0x00000bd1 0x00000000 0x000002f4
					0x00000001 0x00000008 0x00000001 0x00000000
					0x00000063 0x0000000f 0x0000006c 0x00000200
					0x00000004 0x00000005 0x00000004 0x0000000b
					0x00000000 0x00000005 0x00000005 0x00000c11
					0x00000000 0x00000000 0x00000000 0x104ab098
					0x002c00a0 0x00008000 0x00030000 0x00030000
					0x00030000 0x00030000 0x00030000 0x00030000
					0x00030000 0x00030000 0x00030000 0x00030000
					0x00030000 0x00030000 0x00030000 0x00030000
					0x00030000 0x00030000 0x00000000 0x00000000
					0x00000000 0x00000000 0x00000000 0x00000000
					0x00000000 0x00000000 0x00060000 0x00060000
					0x00000000 0x00060000 0x00060000 0x00000000
					0x00000000 0x00000000 0x00000000 0x00000000
					0x00000000 0x00000000 0x00000000 0x00000000
					0x00000000 0x00000000 0x00000000 0x00000000
					0x00000000 0x00000000 0x00000000 0x00000000
					0x00000000 0x00000000 0x00000000 0x00000000
					0x00000000 0x00000000 0x00000000 0x00000000
					0x00048000 0x00048000 0x00048000 0x00048000
					0x00004800 0x00004800 0x00004800 0x00004800
					0x10000280 0x00000000 0x00111111 0x01231339
					0x00000000 0x00000000 0x77ffc081 0x00000000
					0x81f1f108 0x07070004 0x00000000 0x016eeeee
					0x51451420 0x00514514 0x00514514 0x51451400
					0x0000003f 0x000000c6 0x00000000 0x00020000
					0x00000100 0x015b000e 0x015b000e 0x00000000
					0x00000003 0x000052a3 0x8000188b 0x00000009
					0x0f000005 0x80000040 0x00000001 0x00000002
					0x00000009 0x00000005 0x00000006 0x00000001
					0x00000002 0x00000008 0x00000002 0x00000002
					0x00000004 0x00000006 0x06040202 0x000d0709
					0x7586120a 0x70000f03 0x001f0000>;
				nvidia,emc-burst-up-down-regs = <0x0000000a 0x000000be
					0x00ff0038 0x00ff0038 0x00ff003c 0x00ff0090
					0x00ff0041 0x00ff0090 0x00ff0041 0x00280049
					0x00ff0080 0x00ff0004 0x00ff0004 0x0008002d
					0x000000ff 0x00ff0004 0x00ff0033 0x00ff0022
					0x00ff0024 0x00ff0037 0x000000ff 0x00000036
					0x00ff00ff 0x00000036 0x00ff00ff 0x00d400ff
					0x00510029 0x00ff00ff 0x00ff00ff 0x00ff0066
					0x00ff0038>;
				nvidia,emc-zcal-cnt-long = <0x00000042>;
				nvidia,emc-acal-interval = <0x001fffff>;
				nvidia,emc-ctt-term-ctrl = <0x00000802>;
				nvidia,emc-cfg = <0x73340000>;
				nvidia,emc-cfg-2 = <0x00000895>;
				nvidia,emc-sel-dpd-ctrl = <0x00040008>;
				nvidia,emc-cfg-dig-dll = <0x002c0068>;
				nvidia,emc-bgbias-ctl0 = <0x00000000>;
				nvidia,emc-auto-cal-config2 = <0x00000000>;
				nvidia,emc-auto-cal-config3 = <0x00000000>;
				nvidia,emc-auto-cal-config = <0xa1430000>;
				nvidia,emc-mode-reset = <0x80000521>;
				nvidia,emc-mode-1 = <0x80100002>;
				nvidia,emc-mode-2 = <0x80200000>;
				nvidia,emc-mode-4 = <0x00000000>;
				nvidia,emc-clock-latency-change = <2180>;
			};
			emc-table@528000 {
				compatible = "nvidia,tegra12-emc-table";
				reg = <528000>;
				clock-frequency = <528000>;
				nvidia,revision = <0x19>;
				nvidia,emc-min-mv = <880>;
				nvidia,gk20a-min-mv = <870>;
				nvidia,src-sel-reg = <0x80000000>;
				nvidia,burst-regs-num = <165>;
				nvidia,burst-up-down-regs-num = <31>;
				nvidia,emc-registers = <0x00000018 0x00000088
					0x00000000 0x00000010 0x00000006 0x00000006
					0x00000009 0x00000002 0x0000000d 0x00000006
					0x00000006 0x00000002 0x00000002 0x00000000
					0x00000003 0x00000003 0x00000007 0x00000002
					0x00000000 0x00000002 0x00000009 0x00040000
					0x00000003 0x00000000 0x00000000 0x00000000
					0x00000000 0x00000001 0x00000010 0x00000013
					0x00000015 0x00000fd6 0x00000000 0x000003f5
					0x00000002 0x0000000b 0x00000001 0x00000000
					0x00000085 0x00000012 0x00000090 0x00000200
					0x00000004 0x00000005 0x00000004 0x00000010
					0x00000000 0x00000006 0x00000006 0x00001017
					0x00000000 0x00000000 0x00000000 0x104ab098
					0xe01200b1 0x00008000 0x0000000a 0x0000000a
					0x0000000a 0x0000000a 0x0000000a 0x0000000a
					0x0000000a 0x0000000a 0x0000000a 0x0000000a
					0x0000000a 0x0000000a 0x0000000a 0x0000000a
					0x0000000a 0x0000000a 0x00000000 0x00000000
					0x00000000 0x00000000 0x00000000 0x00000000
					0x00000000 0x00000000 0x00044000 0x00044000
					0x00000000 0x00044000 0x00044000 0x00000000
					0x00000000 0x00000000 0x00000000 0x00000000
					0x00000000 0x00000000 0x00000000 0x00000000
					0x00000004 0x00000003 0x00000002 0x00000004
					0x00000003 0x00000002 0x00000003 0x00000003
					0x00000004 0x00000003 0x00000002 0x00000004
					0x00000003 0x00000002 0x00000003 0x00000003
					0x0000000e 0x0000000e 0x0000000e 0x0000000e
					0x0000000e 0x0000000e 0x0000000e 0x0000000e
					0x100002a0 0x00000000 0x00111111 0x0123133d
					0x00000000 0x00000000 0x77ffc085 0x00000000
					0x81f1f108 0x07070004 0x00000000 0x016eeeee
					0x51451420 0x00514514 0x00514514 0x51451400
					0x0606003f 0x00000000 0x00000000 0x00020000
					0x00000100 0x0139000e 0x0139000e 0x00000000
					0x00000003 0x000042a0 0x80002062 0x0000000b
					0x0f000007 0x80000040 0x00000002 0x00000003
					0x0000000c 0x00000007 0x00000008 0x00000001
					0x00000002 0x00000009 0x00000002 0x00000002
					0x00000005 0x00000006 0x06050202 0x0010090c
					0x7428180d 0x70000f03 0x001f0000>;
				nvidia,emc-burst-up-down-regs = <0x0000000d 0x000000fd
					0x00c10038 0x00c10038 0x00c1003c 0x00c10090
					0x00c10041 0x00c10090 0x00c10041 0x00270049
					0x00c10080 0x00c10004 0x00c10004 0x00080021
					0x000000c1 0x00c10004 0x00c10026 0x00c1001a
					0x00c10024 0x00c10029 0x000000c1 0x00000036
					0x00c100c1 0x00000036 0x00c100c1 0x00d400ff
					0x00510029 0x00c100c1 0x00c100c1 0x00c10065
					0x00c1002a>;
				nvidia,emc-zcal-cnt-long = <0x00000042>;
				nvidia,emc-acal-interval = <0x001fffff>;
				nvidia,emc-ctt-term-ctrl = <0x00000802>;
				nvidia,emc-cfg = <0x73300000>;
				nvidia,emc-cfg-2 = <0x0000089d>;
				nvidia,emc-sel-dpd-ctrl = <0x00040008>;
				nvidia,emc-cfg-dig-dll = <0xe0120069>;
				nvidia,emc-bgbias-ctl0 = <0x00000000>;
				nvidia,emc-auto-cal-config2 = <0x00000000>;
				nvidia,emc-auto-cal-config3 = <0x00000000>;
				nvidia,emc-auto-cal-config = <0xa1430000>;
				nvidia,emc-mode-reset = <0x80000941>;
				nvidia,emc-mode-1 = <0x80100002>;
				nvidia,emc-mode-2 = <0x80200008>;
				nvidia,emc-mode-4 = <0x00000000>;
				nvidia,emc-clock-latency-change = <1440>;
			};
			emc-table@600000 {
				compatible = "nvidia,tegra12-emc-table";
				reg = <600000>;
				clock-frequency = <600000>;
				nvidia,revision = <0x19>;
				nvidia,emc-min-mv = <910>;
				nvidia,gk20a-min-mv = <910>;
				nvidia,src-sel-reg = <0xe0000000>;
				nvidia,burst-regs-num = <165>;
				nvidia,burst-up-down-regs-num = <31>;
				nvidia,emc-registers = <0x0000001b 0x0000009b
					0x00000000 0x00000013 0x00000007 0x00000007
					0x0000000b 0x00000003 0x00000010 0x00000007
					0x00000007 0x00000002 0x00000002 0x00000000
					0x00000005 0x00000005 0x0000000a 0x00000002
					0x00000000 0x00000003 0x0000000b 0x00070000
					0x00000003 0x00000000 0x00000000 0x00000000
					0x00000000 0x00000002 0x00000012 0x00000016
					0x00000018 0x00001208 0x00000000 0x00000482
					0x00000002 0x0000000d 0x00000001 0x00000000
					0x00000097 0x00000015 0x000000a3 0x00000200
					0x00000004 0x00000005 0x00000004 0x00000013
					0x00000000 0x00000006 0x00000006 0x00001248
					0x00000000 0x00000000 0x00000000 0x104ab098
					0xe00e00b1 0x00008000 0x0000000a 0x0000000a
					0x0000000a 0x0000000a 0x0000000a 0x0000000a
					0x0000000a 0x0000000a 0x0000000a 0x0000000a
					0x0000000a 0x0000000a 0x0000000a 0x0000000a
					0x0000000a 0x0000000a 0x00000000 0x00000000
					0x00000000 0x00000000 0x00000000 0x00000000
					0x00000000 0x00000000 0x00038000 0x00038000
					0x00000000 0x00038000 0x00038000 0x00000000
					0x00000000 0x00000000 0x00000000 0x00000000
					0x00000000 0x00000000 0x00000000 0x00000000
					0x00000006 0x00000005 0x00000004 0x00000006
					0x00000005 0x00000004 0x00000005 0x00000005
					0x00000006 0x00000005 0x00000004 0x00000006
					0x00000005 0x00000004 0x00000005 0x00000005
					0x0000000e 0x0000000e 0x0000000e 0x0000000e
					0x0000000e 0x0000000e 0x0000000e 0x0000000e
					0x100002a0 0x00000000 0x00111111 0x0121113d
					0x00000000 0x00000000 0x77ffc085 0x00000000
					0x81f1f108 0x07070004 0x00000000 0x016eeeee
					0x51451420 0x00514514 0x00514514 0x51451400
					0x0606003f 0x00000000 0x00000000 0x00020000
					0x00000100 0x0127000e 0x0127000e 0x00000000
					0x00000003 0x000040a0 0x800024a9 0x0000000e
					0x00000009 0x80000040 0x00000003 0x00000004
					0x0000000e 0x00000009 0x0000000a 0x00000001
					0x00000003 0x0000000b 0x00000002 0x00000002
					0x00000005 0x00000007 0x07050202 0x00130b0e
					0x73a91b0f 0x70000f03 0x001f0000>;
				nvidia,emc-burst-up-down-regs = <0x0000000f 0x00000120
					0x00aa0038 0x00aa0038 0x00aa003c 0x00aa0090
					0x00aa0041 0x00aa0090 0x00aa0041 0x00270049
					0x00aa0080 0x00aa0004 0x00aa0004 0x0008001d
					0x000000aa 0x00aa0004 0x00aa0022 0x00aa0018
					0x00aa0024 0x00aa0024 0x000000aa 0x00000036
					0x00aa00aa 0x00000036 0x00aa00aa 0x00d400ff
					0x00510029 0x00aa00aa 0x00aa00aa 0x00aa0065
					0x00aa0025>;
				nvidia,emc-zcal-cnt-long = <0x00000042>;
				nvidia,emc-acal-interval = <0x001fffff>;
				nvidia,emc-ctt-term-ctrl = <0x00000802>;
				nvidia,emc-cfg = <0x73300000>;
				nvidia,emc-cfg-2 = <0x0000089d>;
				nvidia,emc-sel-dpd-ctrl = <0x00040008>;
				nvidia,emc-cfg-dig-dll = <0xe00e0069>;
				nvidia,emc-bgbias-ctl0 = <0x00000000>;
				nvidia,emc-auto-cal-config2 = <0x00000000>;
				nvidia,emc-auto-cal-config3 = <0x00000000>;
				nvidia,emc-auto-cal-config = <0xa1430000>;
				nvidia,emc-mode-reset = <0x80000b61>;
				nvidia,emc-mode-1 = <0x80100002>;
				nvidia,emc-mode-2 = <0x80200010>;
				nvidia,emc-mode-4 = <0x00000000>;
				nvidia,emc-clock-latency-change = <1440>;
			};
			emc-table@792000 {
				compatible = "nvidia,tegra12-emc-table";
				reg = <792000>;
				clock-frequency = <792000>;
				nvidia,revision = <0x19>;
				nvidia,emc-min-mv = <980>;
				nvidia,gk20a-min-mv = <980>;
				nvidia,src-sel-reg = <0x80000000>;
				nvidia,burst-regs-num = <165>;
				nvidia,burst-up-down-regs-num = <31>;
				nvidia,emc-registers = <0x00000024 0x000000cd
					0x00000000 0x00000019 0x0000000a 0x00000008
					0x0000000d 0x00000004 0x00000013 0x0000000a
					0x0000000a 0x00000004 0x00000002 0x00000000
					0x00000006 0x00000006 0x0000000b 0x00000002
					0x00000000 0x00000002 0x0000000d 0x00080000
					0x00000004 0x00000000 0x00000000 0x00000000
					0x00000000 0x00000001 0x00000014 0x00000018
					0x0000001a 0x000017e2 0x00000000 0x000005f8
					0x00000003 0x00000011 0x00000001 0x00000000
					0x000000c7 0x00000018 0x000000d7 0x00000200
					0x00000005 0x00000006 0x00000005 0x00000019
					0x00000000 0x00000008 0x00000008 0x00001822
					0x00000000 0x00000000 0x00000000 0x104ab098
					0xe00700b1 0x00008000 0x007fc008 0x007fc008
					0x007fc008 0x007fc008 0x007fc008 0x007fc008
					0x007fc008 0x007fc008 0x007fc008 0x007fc008
					0x007fc008 0x007fc008 0x007fc008 0x007fc008
					0x007fc008 0x007fc008 0x00000000 0x00000000
					0x00000000 0x00000000 0x00000000 0x00000000
					0x00000000 0x00000000 0x00024000 0x00024000
					0x00000000 0x00024000 0x00024000 0x00000000
					0x00000000 0x00000000 0x00000000 0x00000000
					0x00000000 0x00000000 0x00000000 0x00000000
					0x00000009 0x00000008 0x00000008 0x0000000a
					0x00000009 0x00000008 0x00000009 0x00000009
					0x00000009 0x00000008 0x00000008 0x0000000a
					0x00000009 0x00000008 0x00000009 0x00000009
					0x007fc00c 0x007fc00c 0x007fc00c 0x007fc00c
					0x0007fc0c 0x0007fc0c 0x0007fc0c 0x0007fc0c
					0x100002a0 0x00000000 0x00111111 0x0120113d
					0x00000000 0x00000000 0x77ffc085 0x00000000
					0x81f1f108 0x07070004 0x00000000 0x016eeeee
					0x61861820 0x00514514 0x00514514 0x61861800
					0x0606003f 0x00000000 0x00000000 0x00020000
					0x00000100 0x00f7000e 0x00f7000e 0x00000000
					0x00000004 0x00004080 0x80003012 0x0000000f
					0x0e00000b 0x80000040 0x00000004 0x00000005
					0x00000013 0x0000000c 0x0000000d 0x00000002
					0x00000003 0x0000000c 0x00000002 0x00000002
					0x00000006 0x00000008 0x08060202 0x00170e13
					0x736c2414 0x70000f02 0x001f0000>;
				nvidia,emc-burst-up-down-regs = <0x00000013 0x0000017c
					0x00810038 0x00810038 0x0081003c 0x00810090
					0x00810041 0x00810090 0x00810041 0x00270049
					0x00810080 0x00810004 0x00810004 0x00080016
					0x00000081 0x00810004 0x00810019 0x00810018
					0x00810024 0x0081001c 0x00000081 0x00000036
					0x00810081 0x00000036 0x00810081 0x00d400ff
					0x00510029 0x00810081 0x00810081 0x00810065
					0x0081001c>;
				nvidia,emc-zcal-cnt-long = <0x00000042>;
				nvidia,emc-acal-interval = <0x001fffff>;
				nvidia,emc-ctt-term-ctrl = <0x00000802>;
				nvidia,emc-cfg = <0x73300000>;
				nvidia,emc-cfg-2 = <0x0000089d>;
				nvidia,emc-sel-dpd-ctrl = <0x00040000>;
				nvidia,emc-cfg-dig-dll = <0xe0070069>;
				nvidia,emc-bgbias-ctl0 = <0x00000000>;
				nvidia,emc-auto-cal-config2 = <0x00000000>;
				nvidia,emc-auto-cal-config3 = <0x00000000>;
				nvidia,emc-auto-cal-config = <0xa1430000>;
				nvidia,emc-mode-reset = <0x80000d71>;
				nvidia,emc-mode-1 = <0x80100002>;
				nvidia,emc-mode-2 = <0x80200018>;
				nvidia,emc-mode-4 = <0x00000000>;
				nvidia,emc-clock-latency-change = <1200>;
			};
			emc-table@924000 {
				compatible = "nvidia,tegra12-emc-table";
				reg = <924000>;
				clock-frequency = <924000>;
				nvidia,revision = <0x19>;
				nvidia,emc-min-mv = <1010>;
				nvidia,gk20a-min-mv = <1010>;
				nvidia,src-sel-reg = <0x80000000>;
				nvidia,burst-regs-num = <165>;
				nvidia,burst-up-down-regs-num = <31>;
				nvidia,emc-registers = <0x0000002b 0x000000f0
					0x00000000 0x0000001e 0x0000000b 0x0000000a
					0x0000000f 0x00000005 0x00000016 0x0000000b
					0x0000000b 0x00000004 0x00000002 0x00000000
					0x00000007 0x00000007 0x0000000d 0x00000002
					0x00000000 0x00000002 0x0000000f 0x000a0000
					0x00000004 0x00000000 0x00000000 0x00000000
					0x00000000 0x00000001 0x00000016 0x0000001a
					0x0000001c 0x00001be7 0x00000000 0x000006f9
					0x00000004 0x00000015 0x00000001 0x00000000
					0x000000e7 0x0000001b 0x000000fb 0x00000200
					0x00000006 0x00000007 0x00000006 0x0000001e
					0x00000000 0x0000000a 0x0000000a 0x00001c28
					0x00000000 0x00000000 0x00000000 0x104ab898
					0xe00400b1 0x00008000 0x007fc006 0x007fc006
					0x007f400b 0x007f8008 0x007fc006 0x007fc008
					0x007fc006 0x007fc006 0x007fc006 0x007fc006
					0x007f400b 0x007f8008 0x007fc006 0x007fc008
					0x007fc006 0x007fc006 0x00000000 0x00000000
					0x00000000 0x00000000 0x00000000 0x00000000
					0x00000000 0x00000000 0x00018000 0x00018000
					0x00000000 0x00018000 0x00018000 0x00000000
					0x00000000 0x00000000 0x00000000 0x00000000
					0x00000000 0x00000000 0x00000000 0x00000000
					0x00000000 0x00000000 0x00000000 0x00000000
					0x00000000 0x00000000 0x00000000 0x00000000
					0x00000000 0x00000000 0x00000000 0x00000000
					0x00000000 0x00000000 0x00000000 0x00000000
					0x00000008 0x00000008 0x00000008 0x00000008
					0x00000008 0x00000008 0x00000008 0x00000008
					0x100002a0 0x00000000 0x00111111 0x0120113d
					0x00000000 0x00000000 0x77ffc085 0x00000000
					0x81f1f108 0x07070004 0x00000000 0x016eeeee
					0x61861820 0x00512511 0x00511492 0x6175d900
					0x0606003f 0x00000000 0x00000000 0x00020000
					0x00000128 0x00cd000e 0x00cd000e 0x00000000
					0x00000004 0x00004080 0x800037ea 0x00000011
					0x0e00000d 0x80000040 0x00000005 0x00000006
					0x00000016 0x0000000e 0x0000000f 0x00000002
					0x00000004 0x0000000e 0x00000002 0x00000002
					0x00000007 0x00000009 0x09070202 0x001a1016
					0x734e2a17 0x70000f02 0x001f0000>;
				nvidia,emc-burst-up-down-regs = <0x00000017 0x000001bb
					0x006e0038 0x006e0038 0x006e003c 0x006e0090
					0x006e0041 0x006e0090 0x006e0041 0x00270049
					0x006e0080 0x006e0004 0x006e0004 0x00080016
					0x0000006e 0x006e0004 0x006e0019 0x006e0018
					0x006e0024 0x006e001b 0x0000006e 0x00000036
					0x006e006e 0x00000036 0x006e006e 0x00d400ff
					0x00510029 0x006e006e 0x006e006e 0x006e0065
					0x006e001c>;
				nvidia,emc-zcal-cnt-long = <0x0000004c>;
				nvidia,emc-acal-interval = <0x001fffff>;
				nvidia,emc-ctt-term-ctrl = <0x00000802>;
				nvidia,emc-cfg = <0x73300000>;
				nvidia,emc-cfg-2 = <0x0000089d>;
				nvidia,emc-sel-dpd-ctrl = <0x00040000>;
				nvidia,emc-cfg-dig-dll = <0xe0040069>;
				nvidia,emc-bgbias-ctl0 = <0x00000000>;
				nvidia,emc-auto-cal-config2 = <0x00000000>;
				nvidia,emc-auto-cal-config3 = <0x00000000>;
				nvidia,emc-auto-cal-config = <0xa1430101>;
				nvidia,emc-mode-reset = <0x80000f15>;
				nvidia,emc-mode-1 = <0x80100002>;
				nvidia,emc-mode-2 = <0x80200020>;
				nvidia,emc-mode-4 = <0x00000000>;
				nvidia,emc-clock-latency-change = <1180>;
			};
		};
	};

	dfll@70040084 {
		vdd-cpu-supply = <&vdd_cpu>;
		nvidia,i2c-fs-rate = <400000>;
		status = "okay";
	};

	/* USB A connector */
	usb@7d000000 {
		status = "okay";
	};

	usb-phy@7d000000 {
		status = "okay";
	};

	usb@7d008000 {
		status = "okay";
	};

	usb-phy@7d008000 {
		status = "okay";
		vbus-supply = <&vdd_usb3_vbus>;
	};

	sdhci@700b0400 {
		cd-gpios = <&gpio TEGRA_GPIO(V, 2) GPIO_ACTIVE_HIGH>;
		cd-inverted;
		no-1-8-v;
		status = "okay";
		bus-width = <4>;
		vqmmc-supply = <&vddio_sdmmc3>;
	};

	sdhci@700b0600 {
		power-gpios = <&gpio TEGRA_GPIO(R, 0) GPIO_ACTIVE_HIGH>;
		bus-width = <8>;
		non-removable;
		status = "okay";
	};

	spi@7000da00 {
		status = "okay";
		spidev@0 {
			compatible = "spidev";
			reg = <0>;
			spi-max-frequency = <25000000>;
		};
	};

	pmc@7000e400 {
		nvidia,invert-interrupt;
		nvidia,suspend-mode = <0>;
		#wake-cells = <3>;
		nvidia,cpu-pwr-good-time = <500>;
		nvidia,cpu-pwr-off-time = <300>;
		nvidia,core-pwr-good-time = <641 3845>;
		nvidia,core-pwr-off-time = <61036>;
		nvidia,core-power-req-active-high;
		nvidia,sys-clock-req-active-high;
		nvidia,reset-gpio = <&gpio TEGRA_GPIO(I, 5) GPIO_ACTIVE_LOW>;

		i2c-thermtrip {
			nvidia,pmu = <&as3722>;
			nvidia,reg-addr = <0x36>;
			nvidia,reg-data = <0x2>;
		};
	};

	clocks {
		compatible = "simple-bus";
		#address-cells = <1>;
		#size-cells = <0>;

		clk32k_in: clock@0 {
			compatible = "fixed-clock";
			reg=<0>;
			#clock-cells = <0>;
			clock-frequency = <32768>;
		};
	};

	regulators {
		compatible = "simple-bus";
		#address-cells = <1>;
		#size-cells = <0>;

		floating: regulator@0 {
			compatible = "regulator-fixed";
			reg = <0>;
			regulator-name = "floating";
		};

		vdd_3v3_reg: regulator@1 {
			compatible = "regulator-fixed";
			reg = <1>;
			regulator-name = "vdd_3v3";
			regulator-min-microvolt = <3300000>;
			regulator-max-microvolt = <3300000>;
			regulator-always-on;
			regulator-boot-on;
			enable-active-high;
			gpio = <&as3722 1 GPIO_ACTIVE_HIGH>;
		};

		vdd_mux: regulator@2 {
			compatible = "regulator-fixed";
			reg = <2>;
			regulator-name = "+VDD_MUX";
			regulator-min-microvolt = <19000000>;
			regulator-max-microvolt = <19000000>;
			regulator-always-on;
			regulator-boot-on;
		};

		vdd_5v0_sys: regulator@3 {
			compatible = "regulator-fixed";
			reg = <3>;
			regulator-name = "+5V_SYS";
			regulator-min-microvolt = <5000000>;
			regulator-max-microvolt = <5000000>;
			regulator-always-on;
			regulator-boot-on;
			vin-supply = <&vdd_mux>;
		};

		vdd_usb3_vbus: regulator@4 {
			compatible = "regulator-fixed";
			reg = <4>;
			regulator-name = "+5V_USB_HS";
			regulator-min-microvolt = <5000000>;
			regulator-max-microvolt = <5000000>;
			regulator-always-on;
			regulator-boot-on;
			vin-supply = <&vdd_5v0_sys>;
		};
	};
};
